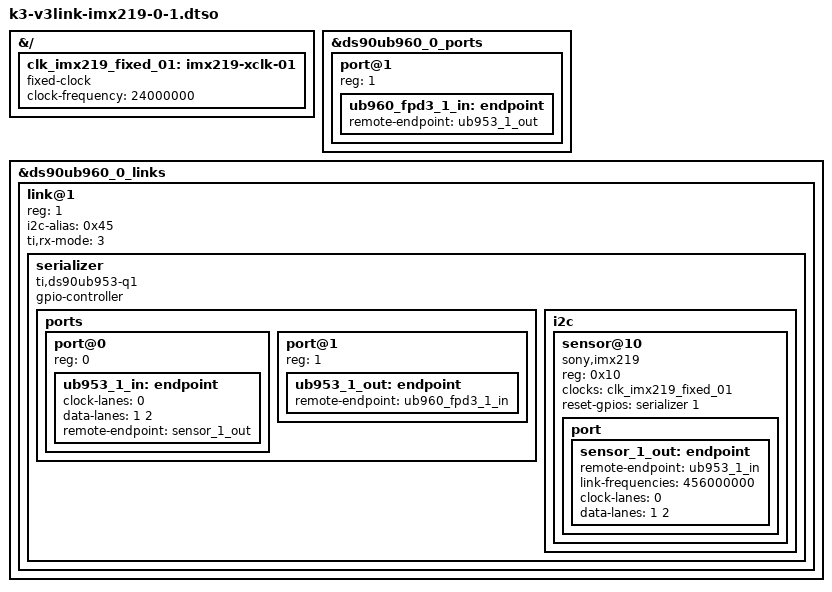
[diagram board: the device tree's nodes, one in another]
// SPDX-License-Identifier: GPL-2.0
/*
 * IMX219 Camera Module for V3-Link d-ch Adapter Board
 * https://docs.arducam.com/V3Link-Camera-Solution/V3Link-Camera-Solution-on-TI-Platform/Introduction/
 *
 * Copyright (c) 2024 Texas Instruments Incorporated - http://www.ti.com/
 */

/dts-v1/;
/plugin/;

#include <dt-bindings/gpio/gpio.h>

&{/} {
	clk_imx219_fixed_01: imx219-xclk-01 {
		compatible = "fixed-clock";
		#clock-cells = <0>;
		clock-frequency = <24000000>;
	};
};

&ds90ub960_0_ports {
	#address-cells = <1>;
	#size-cells = <0>;

	/* FPDLink RX 1 */
	port@1 {
		reg = <1>;

		ub960_fpd3_1_in: endpoint {
			remote-endpoint = <&ub953_1_out>;
		};
	};
};

&ds90ub960_0_links {
	#address-cells = <1>;
	#size-cells = <0>;

	link@1 {
		reg = <1>;
		i2c-alias = <0x45>;

		ti,rx-mode = <3>;

		serializer: serializer {
			compatible = "ti,ds90ub953-q1";
			gpio-controller;
			#gpio-cells = <2>;

			#clock-cells = <0>;

			ports {
				#address-cells = <1>;
				#size-cells = <0>;

				port@0 {
					reg = <0>;
					ub953_1_in: endpoint {
						clock-lanes = <0>;
						data-lanes = <1 2>;
						remote-endpoint = <&sensor_1_out>;
					};
				};

				port@1 {
					reg = <1>;

					ub953_1_out: endpoint {
						remote-endpoint = <&ub960_fpd3_1_in>;
					};
				};
			};

			i2c {
				#address-cells = <1>;
				#size-cells = <0>;

				sensor@10 {
					compatible = "sony,imx219";
					reg = <0x10>;

					clocks = <&clk_imx219_fixed_01>;
					clock-names = "xclk";
					reset-gpios = <&serializer 1 GPIO_ACTIVE_HIGH>;

					port {
						sensor_1_out: endpoint {
							remote-endpoint = <&ub953_1_in>;
							link-frequencies = /bits/ 64 <456000000>;
							clock-lanes = <0>;
							data-lanes = <1 2>;
						};
					};
				};
			};
		};
	};
};
